# ESP32-S31 register map
Vendor: ESPRESSIF SYSTEMS (SHANGHAI) CO., LTD.; Series: ESP32 S-Series; File version: 1
CPU: RV32IMAFC r0p0, little endian, no MPU, FPU, 0 interrupt priority bits
Address unit: 32 bits
Registers are 32-bit, read-write, reset 0x0 unless marked. A register's access mark holds for its fields unless they carry their own. Offsets are from the block's base; [hi:lo] are bit positions; {n}, {i} and the like mark numbered series.

## ADC — ADC (Analog to Digital Converter)
Base 0x20815000
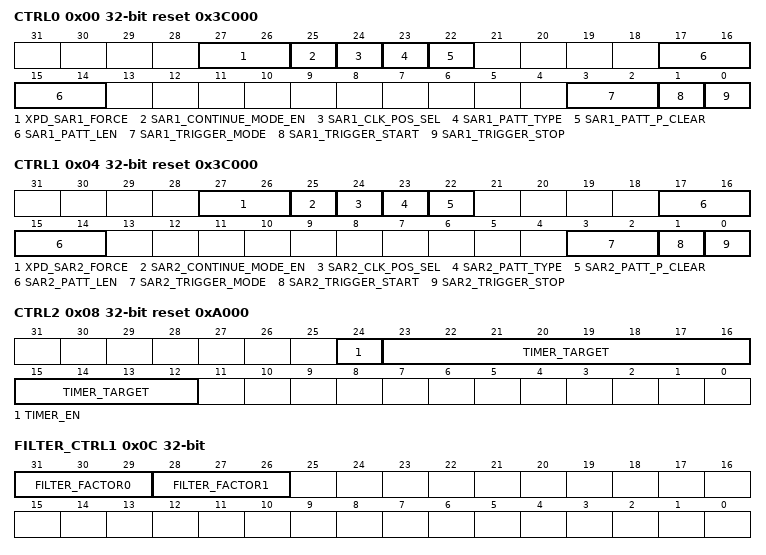
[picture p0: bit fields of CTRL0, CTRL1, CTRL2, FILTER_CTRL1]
0x00 CTRL0 access per field reset 0x3C000 — Register
  [27:26] XPD_SAR1_FORCE rw — force option to xpd sar1 blocks
  [25] SAR1_CONTINUE_MODE_EN rw — 1: I2S input data is from SAR ADC (for DMA), 0: I2S input data is from GPIO matrix
  [24] SAR1_CLK_POS_SEL rw — 1: sar_sel will be coded by the MSB of the 16-bit output data, in this case the resolution should not be larger than 11 bits.
  [23] SAR1_PATT_TYPE rw — 1: select meas start as table update 0:select mead done as table update
  [22] SAR1_PATT_P_CLEAR wo — clear the pointer of pattern table for DIG ADC1 CTRL
  [17:14] SAR1_PATT_LEN rw — 0 ~ 15 means length 1 ~ 16
  [3:2] SAR1_TRIGGER_MODE rw — SAR clock divider
  [1] SAR1_TRIGGER_START wo — need_des
  [0] SAR1_TRIGGER_STOP wo — need_des
0x04 CTRL1 access per field reset 0x3C000 — Register
  [27:26] XPD_SAR2_FORCE rw — force option to xpd sar1 blocks
  [25] SAR2_CONTINUE_MODE_EN rw — 1: I2S input data is from SAR ADC (for DMA), 0: I2S input data is from GPIO matrix
  [24] SAR2_CLK_POS_SEL rw — 1: sar_sel will be coded by the MSB of the 16-bit output data, in this case the resolution should not be larger than 11 bits.
  [23] SAR2_PATT_TYPE rw — 1: select meas start as table update 0:select mead done as table update
  [22] SAR2_PATT_P_CLEAR wo — clear the pointer of pattern table for DIG ADC1 CTRL
  [17:14] SAR2_PATT_LEN rw — 0 ~ 15 means length 1 ~ 16
  [3:2] SAR2_TRIGGER_MODE rw — SAR clock divider
  [1] SAR2_TRIGGER_START wo — need_des
  [0] SAR2_TRIGGER_STOP wo — need_des
0x08 CTRL2 reset 0xA000 — Register
  [24] TIMER_EN — to enable saradc timer trigger
  [23:12] TIMER_TARGET — to set saradc timer target
0x0C FILTER_CTRL1 — Register
  [31:29] FILTER_FACTOR0 — need_des
  [28:26] FILTER_FACTOR1 — need_des
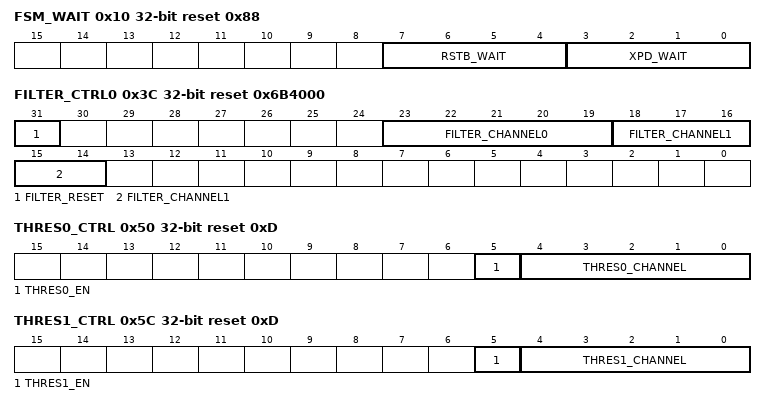
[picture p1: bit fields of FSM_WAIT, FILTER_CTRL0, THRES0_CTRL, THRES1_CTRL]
0x10 FSM_WAIT reset 0x88 — Register
  [7:4] RSTB_WAIT — need_des
  [3:0] XPD_WAIT — need_des
0x14 SAR1_STATUS ro — Register
  [31:29] SAR1_STATE
0x18 SAR2_STATUS ro — Register
  [31:29] SAR2_STATE
0x1C SAR1_PATT_TAB1 reset 0xF00000 — Register
  [23:0] SAR1_PATT_TAB1 — item 0 ~ 3 for pattern table 1 (each item one byte)
{0x18+4i} SAR1_PATT_TAB{i} (i=2..4) — Register
  [23:0] SAR1_PATT_TAB{i} — Item {4i-4} ~ {4i-1} for pattern table 1 (each item one byte)
0x2C SAR2_PATT_TAB1 reset 0xF00000 — Register
  [23:0] SAR2_PATT_TAB1 — item 0 ~ 3 for pattern table 2 (each item one byte)
{0x28+4i} SAR2_PATT_TAB{i} (i=2..4) — Register
  [23:0] SAR2_PATT_TAB{i} — Item {4i-4} ~ {4i-1} for pattern table 2 (each item one byte)
0x3C FILTER_CTRL0 access per field reset 0x6B4000 — Register
  [31] FILTER_RESET wo — enable apb_adc1_filter
  [23:19] FILTER_CHANNEL0 rw — apb_adc1_filter_factor
  [18:14] FILTER_CHANNEL1 rw — need_des
0x40 SAR1_DATA_STATUS ro — Register
  [21:0] APB_SARADC1_DATA — need_des
0x44 SAR2_DATA_STATUS ro — Register
  [21:0] APB_SARADC2_DATA — need_des
0x48 THRES0_HIGH_THRES reset 0xFF — Register
  [16:0] THRES0_HIGH — need_des
0x4C THRES0_LOW_THRES — Register
  [16:0] THRES0_LOW — need_des
0x50 THRES0_CTRL reset 0xD — Register
  [5] THRES0_EN — need_des
  [4:0] THRES0_CHANNEL — need_des
0x54 THRES1_HIGH_THRES reset 0xFF — Register
  [16:0] THRES1_HIGH — need_des
0x58 THRES1_LOW_THRES — Register
  [16:0] THRES1_LOW — need_des
0x5C THRES1_CTRL reset 0xD — Register
  [5] THRES1_EN — need_des
  [4:0] THRES1_CHANNEL — need_des
0x60 THRES_CTRL — Register
  [27] THRES_ALL_EN — need_des
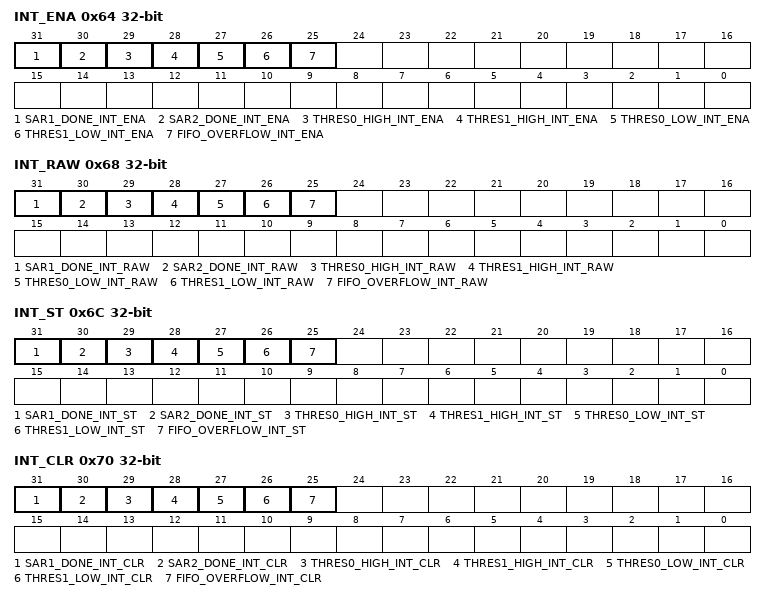
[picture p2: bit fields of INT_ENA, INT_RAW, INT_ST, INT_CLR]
0x64 INT_ENA — Register
  [31] SAR1_DONE_INT_ENA — need_des
  [30] SAR2_DONE_INT_ENA — need_des
  [29] THRES0_HIGH_INT_ENA — need_des
  [28] THRES1_HIGH_INT_ENA — need_des
  [27] THRES0_LOW_INT_ENA — need_des
  [26] THRES1_LOW_INT_ENA — need_des
  [25] FIFO_OVERFLOW_INT_ENA — need_des
0x68 INT_RAW — Register
  [31] SAR1_DONE_INT_RAW — need_des
  [30] SAR2_DONE_INT_RAW — need_des
  [29] THRES0_HIGH_INT_RAW — need_des
  [28] THRES1_HIGH_INT_RAW — need_des
  [27] THRES0_LOW_INT_RAW — need_des
  [26] THRES1_LOW_INT_RAW — need_des
  [25] FIFO_OVERFLOW_INT_RAW — need_des
0x6C INT_ST ro — Register
  [31] SAR1_DONE_INT_ST — need_des
  [30] SAR2_DONE_INT_ST — need_des
  [29] THRES0_HIGH_INT_ST — need_des
  [28] THRES1_HIGH_INT_ST — need_des
  [27] THRES0_LOW_INT_ST — need_des
  [26] THRES1_LOW_INT_ST — need_des
  [25] FIFO_OVERFLOW_INT_ST — need_des
0x70 INT_CLR wo — Register
  [31] SAR1_DONE_INT_CLR — need_des
  [30] SAR2_DONE_INT_CLR — need_des
  [29] THRES0_HIGH_INT_CLR — need_des
  [28] THRES1_HIGH_INT_CLR — need_des
  [27] THRES0_LOW_INT_CLR — need_des
  [26] THRES1_LOW_INT_CLR — need_des
  [25] FIFO_OVERFLOW_INT_CLR — need_des
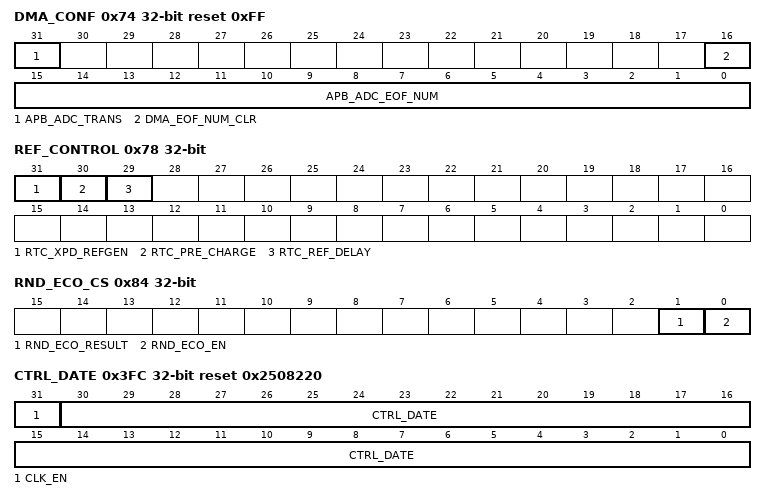
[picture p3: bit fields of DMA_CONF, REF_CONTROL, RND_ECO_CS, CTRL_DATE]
0x74 DMA_CONF access per field reset 0xFF — Register
  [31] APB_ADC_TRANS rw — enable apb_adc use spi_dma
  [16] DMA_EOF_NUM_CLR wo — clear eof cnt
  [15:0] APB_ADC_EOF_NUM rw — the dma_in_suc_eof gen when sample cnt = spi_eof_num
0x78 REF_CONTROL — Register
  [31] RTC_XPD_REFGEN — control the refgen module power up
  [30] RTC_PRE_CHARGE — control the refgen module pre charge
  [29] RTC_REF_DELAY — control the refgen short vdd
0x7C RND_ECO_LOW — Register
  [31:0] ADC_RND_ECO_LOW — rnd eco low
0x80 RND_ECO_HIGH reset 0xFFFFFFFF — Register
  [31:0] ADC_RND_ECO_HIGH — rnd eco high
0x84 RND_ECO_CS access per field — Register
  [1] RND_ECO_RESULT ro — need_des
  [0] RND_ECO_EN rw — need_des
0x3FC CTRL_DATE reset 0x2508220 — Register
  [31] CLK_EN — need_des
  [30:0] CTRL_DATE — need_des

## Notices in the file
Copyright 2026 Espressif Systems (Shanghai) PTE LTD
Licensed under the Apache License, Version 2.0 (the "License");
you may not use this file except in compliance with the License.
You may obtain a copy of the License at
http://www.apache.org/licenses/LICENSE-2.0
Unless required by applicable law or agreed to in writing, software
distributed under the License is distributed on an "AS IS" BASIS,
WITHOUT WARRANTIES OR CONDITIONS OF ANY KIND, either express or implied.
See the License for the specific language governing permissions and
limitations under the License.
